# STM32L562 register map
File version: 1.1
Registers are 32-bit, read-write, reset 0x0 unless marked. A register's access mark holds for its fields unless they carry their own. Offsets are from the block's base; lines under a group give offsets from that group; [hi:lo] are bit positions; {n}, {i} and the like mark numbered series; 'fields as' and 'values as' point back to an identical list; <NAME> marks a mode.

## Memory map
0x40022000 FLASH size 0x400

## Interrupts
6 FLASH — Flash global interrupt
7 FLASH_S (FLASH) — Flash memory secure global interrupt

## FLASH
Base 0x40022000
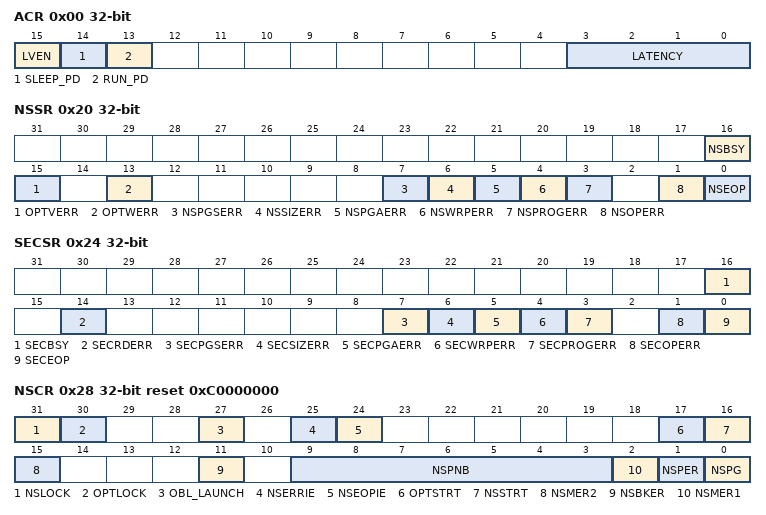
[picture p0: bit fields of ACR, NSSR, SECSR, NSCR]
0x00 ACR — Access control register
  [15] LVEN
  [14] SLEEP_PD — Flash Power-down mode during Low-power sleep mode
  [13] RUN_PD — Flash Power-down mode during Low-power run mode
  [3:0] LATENCY
0x04 PDKEYR wo — Power down key register
  [31:0] PDKEYR — RUN_PD in FLASH_ACR key
0x08 NSKEYR wo — Flash non-secure key register
0x0C SECKEYR wo — Flash secure key register
0x10 OPTKEYR wo — Flash option key register
0x14 LVEKEYR wo — Flash low voltage key register
0x20 NSSR access per field — Flash status register
  [16] NSBSY ro — NSBusy
  [15] OPTVERR rw
  [13] OPTWERR rw
  [7] NSPGSERR rw
  [6] NSSIZERR rw
  [5] NSPGAERR rw
  [4] NSWRPERR rw
  [3] NSPROGERR rw
  [1] NSOPERR rw
  [0] NSEOP rw
0x24 SECSR access per field — Flash status register
  [16] SECBSY ro — SECBusy
  [14] SECRDERR rw — Secure read protection error
  [7] SECPGSERR rw
  [6] SECSIZERR rw
  [5] SECPGAERR rw
  [4] SECWRPERR rw
  [3] SECPROGERR rw
  [1] SECOPERR rw
  [0] SECEOP rw
0x28 NSCR reset 0xC0000000 — Flash non-secure control register
  [31] NSLOCK
  [30] OPTLOCK — Options Lock
  [27] OBL_LAUNCH — Force the option byte loading
  [25] NSERRIE
  [24] NSEOPIE
  [17] OPTSTRT — Options modification start
  [16] NSSTRT — Options modification start
  [15] NSMER2
  [11] NSBKER
  [9:3] NSPNB
  [2] NSMER1
  [1] NSPER
  [0] NSPG
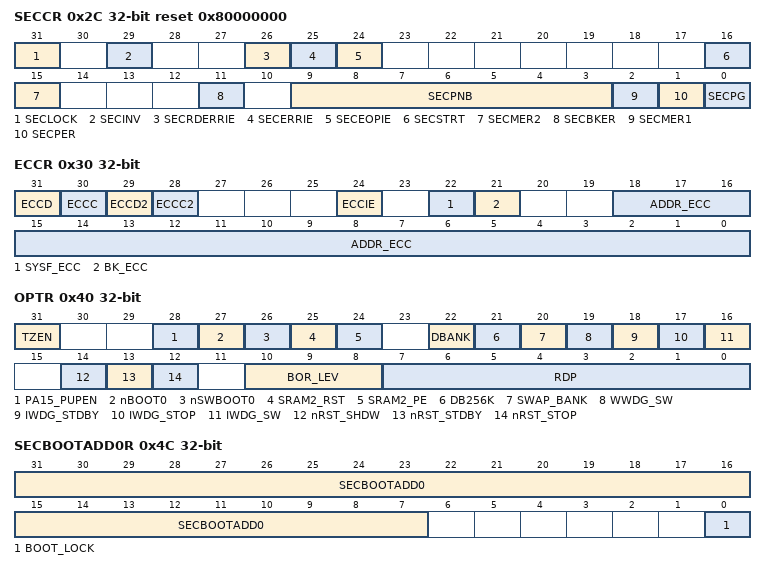
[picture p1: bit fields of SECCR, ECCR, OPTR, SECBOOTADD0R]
0x2C SECCR reset 0x80000000 — Flash secure control register
  [31] SECLOCK, [29] SECINV, [26] SECRDERRIE, [25] SECERRIE, [24] SECEOPIE, [16] SECSTRT, [15] SECMER2, [11] SECBKER, [9:3] SECPNB, [2] SECMER1, [1] SECPER, [0] SECPG
0x30 ECCR access per field — Flash ECC register
  [31] ECCD rw — ECC detection
  [30] ECCC rw — ECC correction
  [29] ECCD2 rw
  [28] ECCC2 rw
  [24] ECCIE rw — ECC correction interrupt enable
  [22] SYSF_ECC ro
  [21] BK_ECC ro
  [18:0] ADDR_ECC ro — ECC fail address
0x40 OPTR — Flash option register
  [31] TZEN
  [28] PA15_PUPEN
  [27] nBOOT0
  [26] nSWBOOT0
  [25] SRAM2_RST — SRAM2 Erase when system reset
  [24] SRAM2_PE — SRAM2 parity check enable
  [22] DBANK
  [21] DB256K
  [20] SWAP_BANK
  [19] WWDG_SW — Window watchdog selection
  [18] IWDG_STDBY — Independent watchdog counter freeze in Standby mode
  [17] IWDG_STOP — Independent watchdog counter freeze in Stop mode
  [16] IWDG_SW — Independent watchdog selection
  [14] nRST_SHDW
  [13] nRST_STDBY
  [12] nRST_STOP
  [10:8] BOR_LEV — BOR reset Level
  [7:0] RDP — Read protection level
0x44 NSBOOTADD0R wo reset 0xF — Flash non-secure boot address 0 register
  [31:7] NSBOOTADD0
0x48 NSBOOTADD1R wo reset 0xF — Flash non-secure boot address 1 register
  [31:7] NSBOOTADD1
0x4C SECBOOTADD0R access per field — FFlash secure boot address 0 register
  [31:7] SECBOOTADD0 wo, [0] BOOT_LOCK rw
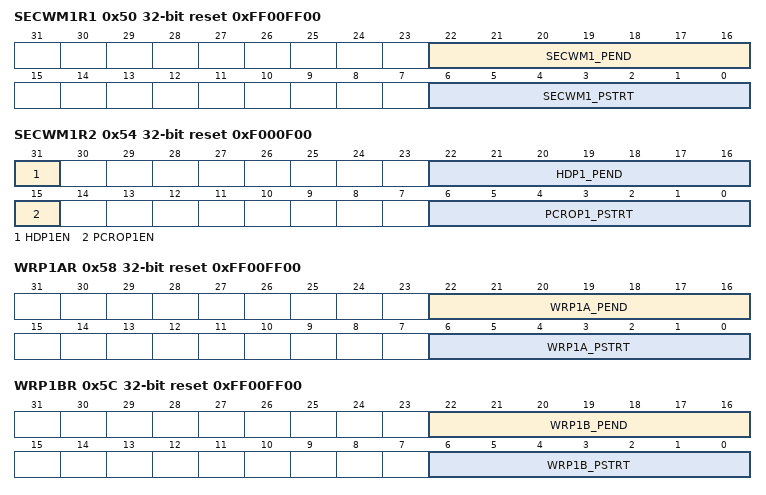
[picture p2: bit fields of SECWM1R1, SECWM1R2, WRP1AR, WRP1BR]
0x50 SECWM1R1 reset 0xFF00FF00 — Flash bank 1 secure watermak1 register
  [22:16] SECWM1_PEND, [6:0] SECWM1_PSTRT
0x54 SECWM1R2 reset 0xF000F00 — Flash secure watermak1 register 2
  [31] HDP1EN, [22:16] HDP1_PEND, [15] PCROP1EN, [6:0] PCROP1_PSTRT
0x58 WRP1AR reset 0xFF00FF00 — Flash Bank 1 WRP area A address register
  [22:16] WRP1A_PEND, [6:0] WRP1A_PSTRT
0x5C WRP1BR reset 0xFF00FF00 — Flash Bank 1 WRP area B address register
  [22:16] WRP1B_PEND, [6:0] WRP1B_PSTRT
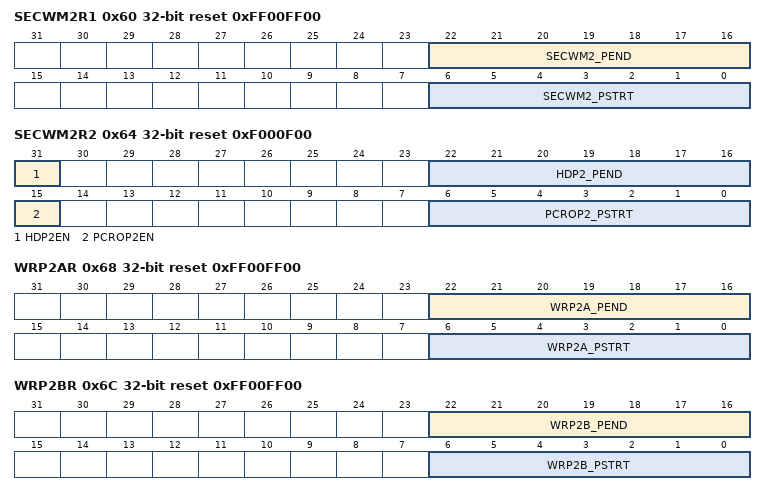
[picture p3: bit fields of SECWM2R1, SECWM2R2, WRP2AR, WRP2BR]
0x60 SECWM2R1 reset 0xFF00FF00 — Flash secure watermak2 register
  [22:16] SECWM2_PEND, [6:0] SECWM2_PSTRT
0x64 SECWM2R2 reset 0xF000F00 — Flash secure watermak2 register2
  [31] HDP2EN, [22:16] HDP2_PEND, [15] PCROP2EN, [6:0] PCROP2_PSTRT
0x68 WRP2AR reset 0xFF00FF00 — Flash WPR2 area A address register
  [22:16] WRP2A_PEND, [6:0] WRP2A_PSTRT
0x6C WRP2BR reset 0xFF00FF00 — Flash WPR2 area B address register
  [22:16] WRP2B_PEND, [6:0] WRP2B_PSTRT
{0x7C+4i} SECBB1R{i} (i=1..4) — FLASH secure block based bank 1 register
  [31:0] SECBB1
{0x9C+4i} SECBB2R{i} (i=1..4) — FLASH secure block based bank 2 register
  [31:0] SECBB2
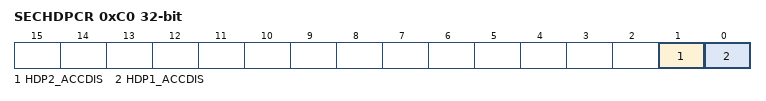
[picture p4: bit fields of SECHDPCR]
0xC0 SECHDPCR — FLASH secure HDP control register
  [1] HDP2_ACCDIS, [0] HDP1_ACCDIS
0xC4 PRIVCFGR — Power privilege configuration register
  [0] PRIV
